# GAP8 register map
Vendor: GreenWaves Technologies SAS; Series: GAP8; File version: 1.3.1
CPU: other r1p0, little endian, MPU, no FPU, I-cache, DTCM, false interrupt priority bits
Registers are 32-bit, read-write, reset 0x0 unless marked. A register's access mark holds for its fields unless they carry their own. Offsets are from the block's base; [hi:lo] are bit positions; {n}, {i} and the like mark numbered series; 'fields as' and 'values as' point back to an identical list.

## uart — uDMA UART interface
Base 0x1A102200
0x00 rx_saddr — uDMA RX UART buffer base address configuration register.
  [15:0] rx_saddr — RX buffer base address bitfield: - Read: returns value of the buffer pointer until transfer is finished. Else returns 0. - Write: sets RX buffer base address
0x04 rx_size — uDMA RX UART buffer size configuration register.
  [16:0] rx_size — RX buffer size bitfield in bytes. (128kBytes maximum) - Read: returns remaining buffer size to transfer. - Write: sets buffer size.
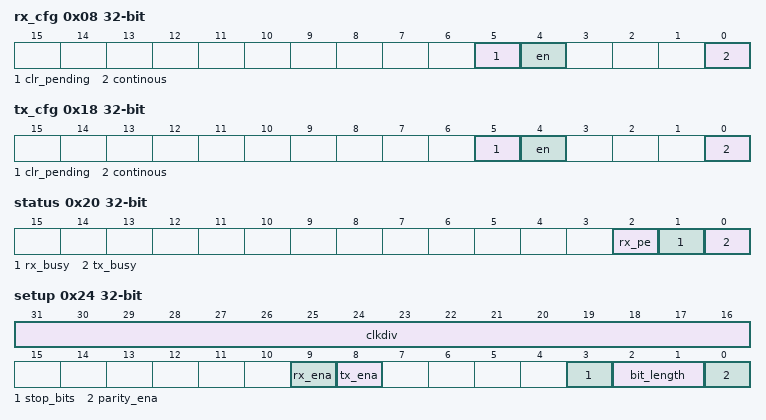
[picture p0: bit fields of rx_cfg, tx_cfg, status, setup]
0x08 rx_cfg — uDMA RX UART stream configuration register.
  [5] clr_pending — RX channel clear and stop transfer RX transfer pending in queue status flag
    on write: 0=disable (feature is disabled); 1=stop and clear the on-going transfer | on read: 0=no pending transfer in the queue; 1=pending transfer in the queue
  [4] en — RX channel enable and start transfer bitfield This signal is used also to queue a transfer if one is already ongoing.
    0=disable (feature is disabled); 1=enable and start the transfer
  [0] continous — RX channel continuous mode bitfield At the end of the buffer transfer, the uDMA reloads the address / buffer size and starts a new transfer.
    0=disabled (feature is disabled); 1=enabled (feature is enabled)
0x10 tx_saddr — uDMA TX UART buffer base address configuration register.
  [15:0] tx_saddr — TX buffer base address bitfield: - Read: returns value of the buffer pointer until transfer is finished. Else returns 0. - Write: sets buffer base address
0x14 tx_size — uDMA TX UART buffer size configuration register.
  [16:0] tx_size — TX buffer size bitfield in bytes. (128kBytes maximum) - Read: returns remaining buffer size to transfer. - Write: sets buffer size.
0x18 tx_cfg — uDMA TX UART stream configuration register.
  [5] clr_pending — TX channel clear and stop transfer bitfield TX transfer pending in queue status flag
    on write: 0=disabled (feature is disabled); 1=stop and clear the on-going transfer | on read: 0=no pending transfer in the queue; 1=pending transfer in the queue
  [4] en — TX channel enable and start transfer bitfield This signal is used also to queue a transfer if one is already ongoing.
    0=disabled (feature is disabled); 1=enable and start the transfer
  [0] continous — TX channel continuous mode bitfield At the end of the buffer transfer, the uDMA reloads the address / buffer size and starts a new transfer.
    values as rx_cfg.continous
0x20 status ro — uDMA UART status register.
  [2] rx_pe — RX parity error status flag
    on read: 0=no_error (set to no error); 1=RX parity error occurred
  [1] rx_busy — RX busy status flag
    on read: 0=no RX transfer on-going; 1=RX transfer on-going
  [0] tx_busy — TX busy status flag
    on read: 0=no TX transfer on-going; 1=TX transfer on-going
0x24 setup — UDMA UART configuration register.
  [31:16] clkdiv — UART Clock divider configuration bitfield. The baudrate is equal to SOC_FREQ/CLKDIV.
  [9] rx_ena — RX transceiver configuration bitfield
    values as rx_cfg.continous
  [8] tx_ena — TX transceiver configuration bitfield
    values as rx_cfg.continous
  [3] stop_bits — Stop bits length bitfield
    0=1_stop_bit (set to 1 stop bit); 1=2_stop_bits (set to 2 stop bits)
  [2:1] bit_length — Character length bitfield
    {v}={v+5}_bits (set to {v+5} bits) (v=0..3)
  [0] parity_ena — Parity bit generation and check configuration bitfield
    values as rx_cfg.continous

## i2c0 — I2C Channel 0
Base 0x1A102280
Same registers: i2c1 0x1A102300
0x00 rx_saddr — uDMA RX I2C buffer base address configuration register.
  [15:0] rx_saddr — RX buffer base address bitfield: - Read: returns value of the buffer pointer until transfer is finished. Else returns 0. - Write: sets RX buffer base address
0x04 rx_size — uDMA RX I2C buffer size configuration register.
  [16:0] rx_size — RX buffer size bitfield in bytes. (128kBytes maximum) - Read: returns remaining buffer size to transfer. - Write: sets buffer size.
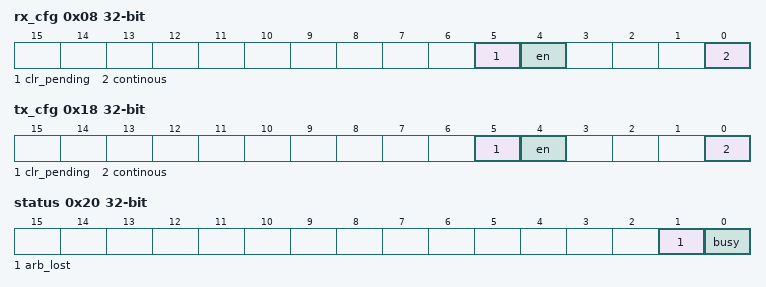
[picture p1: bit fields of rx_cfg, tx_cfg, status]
0x08 rx_cfg — uDMA RX I2C stream configuration register.
  [5] clr_pending — RX channel clear and stop transfer RX transfer pending in queue status flag
    on write: 0=disable (feature is disabled); 1=stop and clear the on-going transfer | on read: 0=no pending transfer in the queue; 1=pending transfer in the queue
  [4] en — RX channel enable and start transfer bitfield This signal is used also to queue a transfer if one is already ongoing.
    0=disable (feature is disabled); 1=enable and start the transfer
  [0] continous — RX channel continuous mode bitfield At the end of the buffer transfer, the uDMA reloads the address / buffer size and starts a new transfer.
    0=disabled (feature is disabled); 1=enabled (feature is enabled)
0x10 tx_saddr — uDMA TX I2C buffer base address configuration register.
  [15:0] tx_saddr — TX buffer base address bitfield: - Read: returns value of the buffer pointer until transfer is finished. Else returns 0. - Write: sets buffer base address
0x14 tx_size — uDMA TX I2C buffer size configuration register.
  [16:0] tx_size — TX buffer size bitfield in bytes. (128kBytes maximum) - Read: returns remaining buffer size to transfer. - Write: sets buffer size.
0x18 tx_cfg — uDMA TX I2C stream configuration register.
  [5] clr_pending — TX channel clear and stop transfer bitfield TX transfer pending in queue status flag
    on write: 0=disabled (feature is disabled); 1=stop and clear the on-going transfer | on read: 0=no pending transfer in the queue; 1=pending transfer in the queue
  [4] en — TX channel enable and start transfer bitfield This signal is used also to queue a transfer if one is already ongoing.
    0=disabled (feature is disabled); 1=enable and start the transfer
  [0] continous — TX channel continuous mode bitfield At the end of the buffer transfer, the uDMA reloads the address / buffer size and starts a new transfer.
    values as rx_cfg.continous
0x20 status — uDMA I2C Status register.
  [1] arb_lost — I2C arbitration lost status flag
    0=no_error (set to no error); 1=arbitration lost error
  [0] busy — I2C bus busy status flag
    0=no transfer on-going; 1=transfer_on-going (set to transfer on-going)
0x24 setup — uDMA I2C Configuration register.
  [0] do_rst — Reset command used to abort the on-going transfer and clear busy and arbitration lost status flags.
